# GD32F1x0 register map
File version: 1.0
CPU: CM3 r2p1, little endian, no MPU, no FPU, 4 interrupt priority bits
Registers are 32-bit, read-write, reset 0x0 unless marked. A register's access mark holds for its fields unless they carry their own. Offsets are from the block's base; [hi:lo] are bit positions.

## USART0 — Universal synchronous asynchronous receiver transmitter
Base 0x40013800
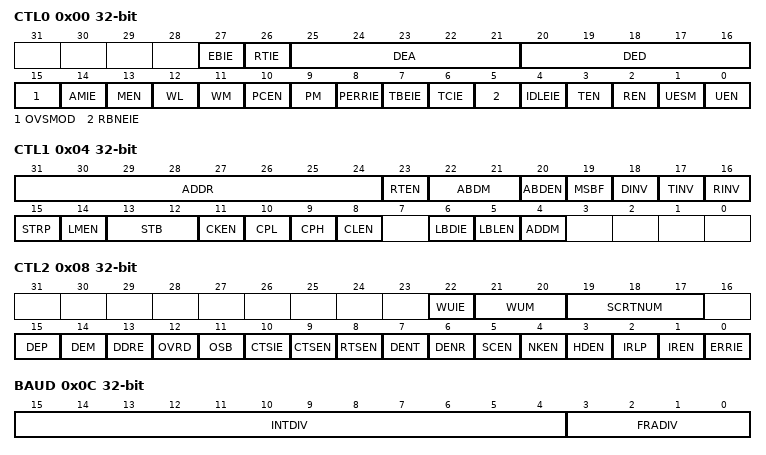
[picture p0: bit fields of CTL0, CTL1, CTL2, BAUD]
0x00 CTL0 — Control register 0
  [27] EBIE — End of Block interrupt enable
  [26] RTIE — Receiver timeout interrupt enable
  [25:21] DEA — Driver Enable assertion time
  [20:16] DED — Driver Enable deassertion time
  [15] OVSMOD — Oversampling mode
  [14] AMIE — ADDR match interrupt enable
  [13] MEN — Mute mode enable
  [12] WL — Word length
  [11] WM — Wakeup method in mute mode
  [10] PCEN — Parity control enable
  [9] PM — Parity selection
  [8] PERRIE — Parity error interrupt enable
  [7] TBEIE — Transmitter register empty interrupt enable
  [6] TCIE — Transmission complete interrupt enable
  [5] RBNEIE — Read data buffer not empty interrupt and overrun error interrupt enable
  [4] IDLEIE — IDLE line detected interrupt enable
  [3] TEN — Transmitter enable
  [2] REN — Receiver enable
  [1] UESM — USART enable in Deep-sleep mode
  [0] UEN — USART enable
0x04 CTL1 — Control register 1
  [31:24] ADDR — Address of the USART terminal
  [23] RTEN — Receiver timeout enable
  [22:21] ABDM — Auto baud rate mode
  [20] ABDEN — Auto baud rate enable
  [19] MSBF — Most significant bit first
  [18] DINV — Data bit level inversion
  [17] TINV — TX pin level inversion
  [16] RINV — RX pin level inversion
  [15] STRP — Swap TX/RX pins
  [14] LMEN — LIN mode enable
  [13:12] STB — STOP bits length
  [11] CKEN — CK pin enable
  [10] CPL — Clock polarity
  [9] CPH — Clock phase
  [8] CLEN — CK length
  [6] LBDIE — LIN break detection interrupt enable
  [5] LBLEN — LIN break frame length
  [4] ADDM — Address detection mode
0x08 CTL2 — Control register 2
  [22] WUIE — Wakeup from Deep-sleep mode interrupt enable
  [21:20] WUM — Wakeup mode from Deep-sleep mode
  [19:17] SCRTNUM — Smartcard auto-retry number
  [15] DEP — Driver enable polarity mode
  [14] DEM — Driver enable mode
  [13] DDRE — Disable DMA on reception error
  [12] OVRD — Overrun Disable
  [11] OSB — One sample bit method
  [10] CTSIE — CTS interrupt enable
  [9] CTSEN — CTS enable
  [8] RTSEN — RTS enable
  [7] DENT — DMA enable transmitter
  [6] DENR — DMA enable for reception
  [5] SCEN — Smartcard mode enable
  [4] NKEN — NKEN enable in Smartcard mode
  [3] HDEN — Half-duplex selection
  [2] IRLP — IrDA low-power
  [1] IREN — IrDA mode enable
  [0] ERRIE — Error interrupt enable
0x0C BAUD — Baud rate generator register
  [15:4] INTDIV — Integer part of baud-rate divider
  [3:0] FRADIV — Fraction part of baud-rate divider
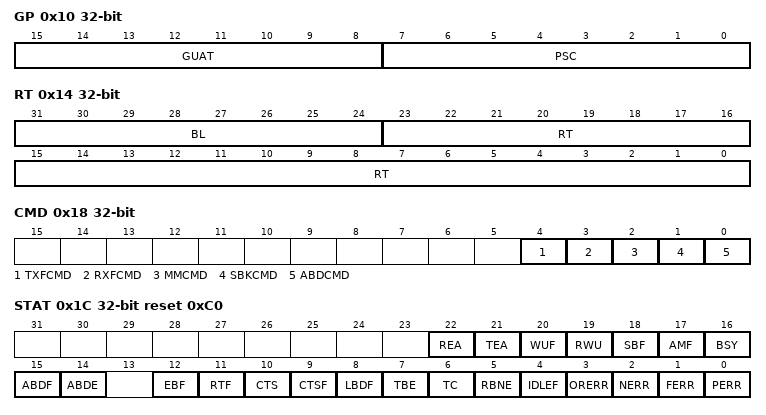
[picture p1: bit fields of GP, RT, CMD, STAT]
0x10 GP — Prescaler and guard time configuration register
  [15:8] GUAT — Guard time value in smartcard mode
  [7:0] PSC — Prescaler value for dividing the system clock
0x14 RT — Receiver timeout register
  [31:24] BL — Block Length
  [23:0] RT — Receiver timeout value
0x18 CMD wo — Request register
  [4] TXFCMD — Transmit data flush request
  [3] RXFCMD — Receive data flush command
  [2] MMCMD — Mute mode command
  [1] SBKCMD — Send break command
  [0] ABDCMD — Auto baudrate detection command
0x1C STAT ro reset 0xC0 — Interrupt & status register
  [22] REA — Receive enable acknowledge flag
  [21] TEA — Transmit enable acknowledge flag
  [20] WUF — Wakeup from Deep-sleep mode flag
  [19] RWU — Receiver wakeup from Mute mode
  [18] SBF — Send break flag
  [17] AMF — ADDR match flag
  [16] BSY — Busy flag
  [15] ABDF — Auto baudrate detection flag
  [14] ABDE — Auto baudrate detection error
  [12] EBF — End of block flag
  [11] RTF — Receiver timeout
  [10] CTS — CTS level
  [9] CTSF — CTS change flag
  [8] LBDF — LIN break detection flag
  [7] TBE — Transmit data register empty
  [6] TC — Transmission complete
  [5] RBNE — Read data buffer not empty
  [4] IDLEF — IDLE line detected flag
  [3] ORERR — Overrun error
  [2] NERR — Noise error flag
  [1] FERR — Frame error flag
  [0] PERR — Parity error flag
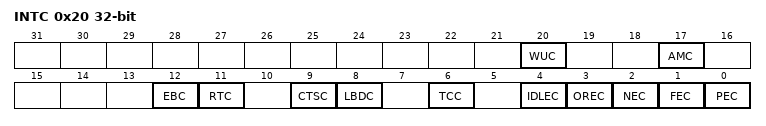
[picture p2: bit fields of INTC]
0x20 INTC wo — Interrupt flag clear register
  [20] WUC — Wakeup from Deep-sleep mode clear
  [17] AMC — ADDR match clear
  [12] EBC — End of timeout clear
  [11] RTC — Receiver timeout clear flag
  [9] CTSC — CTS change clear
  [8] LBDC — LIN break detected clear
  [6] TCC — Transmission complete clear flag
  [4] IDLEC — Idle line detected clear
  [3] OREC — Overrun error clear flag
  [2] NEC — Noise detected clear
  [1] FEC — Framing error clear flag
  [0] PEC — Parity error clear flag
0x24 RDATA ro — Receive data register
  [8:0] RDATA — Receive data value
0x28 TDATA — Transmit data register
  [8:0] TDATA — Transmit data value
